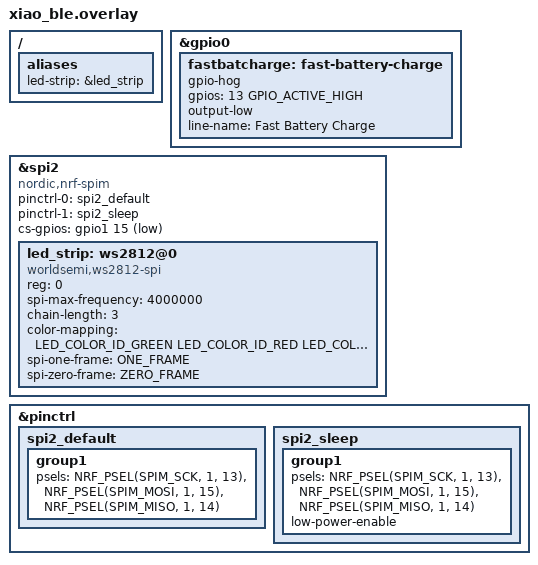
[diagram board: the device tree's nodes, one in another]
#include <dt-bindings/led/led.h>

&gpio0 {
    fastbatcharge: fast-battery-charge {
        gpio-hog;
        gpios = <13 GPIO_ACTIVE_HIGH>;
        output-low;
        line-name = "Fast Battery Charge";
    };
};

&spi2 {
	compatible = "nordic,nrf-spim";
	status = "okay";
	pinctrl-0 = <&spi2_default>;
	pinctrl-1 = <&spi2_sleep>;
	cs-gpios = <&gpio1 15 GPIO_ACTIVE_LOW>; // D10
    pinctrl-names = "default", "sleep";

	led_strip: ws2812@0 {
		compatible = "worldsemi,ws2812-spi";

		/* SPI */
		reg = <0>; /* ignored, but necessary for SPI bindings */
		spi-max-frequency = <4000000>;

		/* WS2812 */
		chain-length = <3>; /* arbitrary; change at will */
		color-mapping = <LED_COLOR_ID_GREEN
				         LED_COLOR_ID_RED
				         LED_COLOR_ID_BLUE>;
		spi-one-frame = <ONE_FRAME>;
		spi-zero-frame = <ZERO_FRAME>;
	};
};

&pinctrl {
    spi2_default: spi2_default {
		group1 {
			psels = <NRF_PSEL(SPIM_SCK, 1, 13)>,
				<NRF_PSEL(SPIM_MOSI, 1, 15)>,
				<NRF_PSEL(SPIM_MISO, 1, 14)>;
		};
	};

	spi2_sleep: spi2_sleep {
		group1 {
			psels = <NRF_PSEL(SPIM_SCK, 1, 13)>,
				<NRF_PSEL(SPIM_MOSI, 1, 15)>,
				<NRF_PSEL(SPIM_MISO, 1, 14)>;
			low-power-enable;
		};
	};
};

/ {
	aliases {
		led-strip = &led_strip;
	};
};
